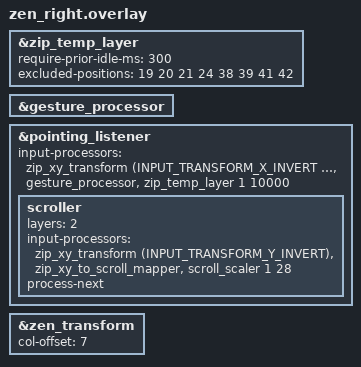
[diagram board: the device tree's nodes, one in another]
#include "zen.dtsi"
#include <input/processors.dtsi>
#include <dt-bindings/zmk/input_transform.h>

/* AML (Auto Mouse Layer) がタイピング中の振動で誤爆しないよう、
 * デフォルトの zip_temp_layer に require-prior-idle-ms を追加する。
 * 直前 300ms 以内にキーコード入力(キー押下)があった場合は、
 * ポインティングデバイスの動きがあってもレイヤーを有効化しない。
 *
 * excluded-positions にはMouse Layerで明示的なキーを割り当てている位置を指定している。
 * AML有効化中にこれらのキーを押してもAMLは解除されず、それ以外のキーを押すと
 * 即座にAMLが解除される。
 *
 * 別ラベルで新規インスタンスを追加する方式は採用しない: ZMK v0.3系の
 * input_processor_temp_layer ドライバは、レイヤー有効化を処理する
 * layer_action_work_cb() 内で `DEVICE_DT_INST_GET(0)` によりインスタンス0の
 * デバイスデータを決め打ちで参照しており(layer_disable_works[]も全インスタンス共有)、
 * 同一compatibleのインスタンスを複数定義すると、実際に有効化されるレイヤーが
 * 意図したインスタンスと異なるインスタンスの状態に基づいてしまう不具合がある。
 * そのため既存の zip_temp_layer 単一インスタンスにプロパティを追加する方式とする。
 */
&zip_temp_layer {
    require-prior-idle-ms = <300>;
    excluded-positions = <19 20 21 24 38 39 41 42>;
};

&gesture_processor {
    status = "okay";
};

&pointing_listener {
    input-processors =
        <&zip_xy_transform (INPUT_TRANSFORM_X_INVERT | INPUT_TRANSFORM_Y_INVERT)>,
        <&gesture_processor>,
        <&zip_temp_layer 1 10000>;

    scroller {
        layers = <2>;
        input-processors =
            <&zip_xy_transform (INPUT_TRANSFORM_Y_INVERT)>,
            <&zip_xy_to_scroll_mapper>,
            <&scroll_scaler 1 28>;
        process-next;
    };
};

&zen_transform {
    col-offset = <7>;
};
